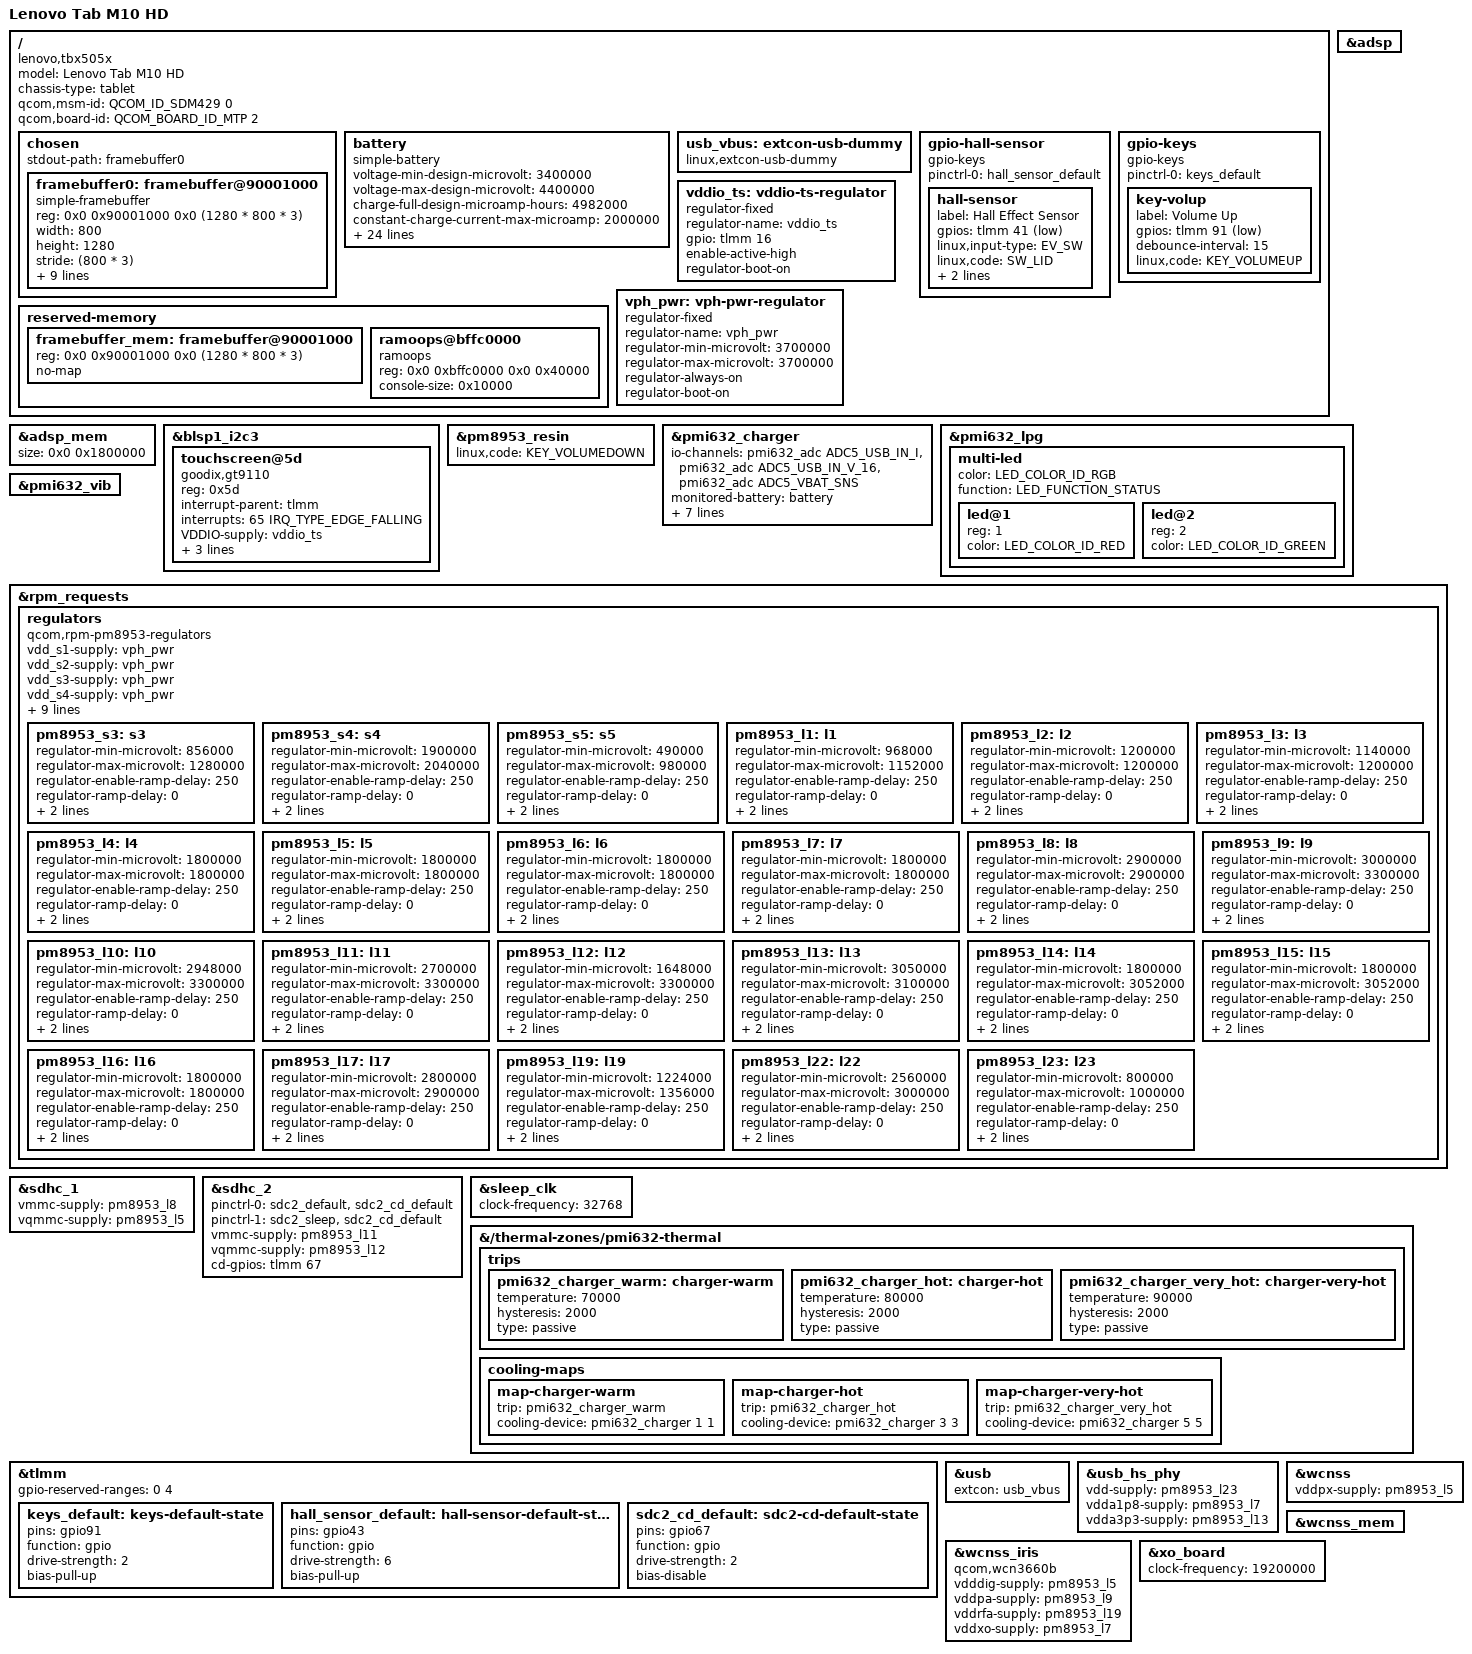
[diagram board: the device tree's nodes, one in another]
// SPDX-License-Identifier: BSD-3-Clause
/*
 * Lenovo Tab M10 HD (TB-X505X) device tree source
 *
 * Copyright (c) 2025 Kaustabh Chakraborty <kauschluss@disroot.org>
 */

/dts-v1/;
#include <dt-bindings/arm/qcom,ids.h>
#include <dt-bindings/gpio/gpio.h>
#include <dt-bindings/leds/common.h>
#include "sdm429.dtsi"
#include "pm8953.dtsi"
#include "pmi632.dtsi"

/ {
	model = "Lenovo Tab M10 HD";
	compatible = "lenovo,tbx505x", "qcom,sdm429";
	chassis-type = "tablet";

	qcom,msm-id = <QCOM_ID_SDM429 0>;
	qcom,board-id = <QCOM_BOARD_ID_MTP 2>;

	chosen {
		#address-cells = <2>;
		#size-cells = <2>;
		ranges;

		stdout-path = "framebuffer0";

		framebuffer0: framebuffer@90001000 {
			compatible = "simple-framebuffer";
			reg = <0x0 0x90001000 0x0 (1280 * 800 * 3)>;
			width = <800>;
			height = <1280>;
			stride = <(800 * 3)>;
			format = "r8g8b8";

			clocks = <&gcc GCC_MDSS_AHB_CLK>,
				 <&gcc GCC_MDSS_AXI_CLK>,
				 <&gcc GCC_MDSS_VSYNC_CLK>,
				 <&gcc GCC_MDSS_MDP_CLK>,
				 <&gcc GCC_MDSS_BYTE0_CLK>,
				 <&gcc GCC_MDSS_PCLK0_CLK>,
				 <&gcc GCC_MDSS_ESC0_CLK>;
			power-domains = <&gcc MDSS_GDSC>;
		};
	};

	battery: battery {
		compatible = "simple-battery";
		voltage-min-design-microvolt = <3400000>;
		voltage-max-design-microvolt = <4400000>;
		charge-full-design-microamp-hours = <4982000>;
		constant-charge-current-max-microamp = <2000000>;
		constant-charge-voltage-max-microvolt = <4400000>;
		charge-term-current-microamp = <170000>;
		factory-internal-resistance-micro-ohms = <120000>;
		id-resistor-ohms = <21000>;

		ocv-capacity-celsius = <25>;
		ocv-capacity-table-0 = <4382700 100>, <4361700 98>, <4339700 96>, <4314400 94>,
			<4289200 92>, <4264600 90>, <4240400 88>, <4216900 86>,
			<4194100 84>, <4171800 82>, <4149400 80>, <4128600 78>,
			<4111200 76>, <4094700 74>, <4072300 72>, <4040700 70>,
			<4014800 68>, <3999700 66>, <3987400 64>, <3973500 62>,
			<3959100 60>, <3941400 58>, <3914200 56>, <3887900 54>,
			<3872900 52>, <3862200 50>, <3852900 48>, <3844900 46>,
			<3837600 44>, <3830500 42>, <3824000 40>, <3818100 38>,
			<3812700 36>, <3807800 34>, <3803900 32>, <3800400 30>,
			<3796700 28>, <3793000 26>, <3788100 24>, <3780000 22>,
			<3769700 20>, <3758500 18>, <3745600 16>, <3730200 14>,
			<3715700 12>, <3706400 10>, <3704000 9>, <3702300 8>,
			<3700700 7>, <3697000 6>, <3675800 5>, <3634000 4>,
			<3577700 3>, <3501200 2>, <3383700 1>, <3000000 0>;
	};

	usb_vbus: extcon-usb-dummy {
		compatible = "linux,extcon-usb-dummy";
	};

	gpio-hall-sensor {
		compatible = "gpio-keys";

		pinctrl-0 = <&hall_sensor_default>;
		pinctrl-names = "default";

		hall-sensor {
			label = "Hall Effect Sensor";
			gpios = <&tlmm 41 GPIO_ACTIVE_LOW>;
			linux,input-type = <EV_SW>;
			linux,code = <SW_LID>;
			linux,can-disable;
			wakeup-source;
		};
	};

	gpio-keys {
		compatible = "gpio-keys";

		pinctrl-0 = <&keys_default>;
		pinctrl-names = "default";

		key-volup {
			label = "Volume Up";
			gpios = <&tlmm 91 GPIO_ACTIVE_LOW>;
			debounce-interval = <15>;
			linux,code = <KEY_VOLUMEUP>;
		};
	};

	reserved-memory {
		framebuffer_mem: framebuffer@90001000 {
			reg = <0x0 0x90001000 0x0 (1280 * 800 * 3)>;
			no-map;
		};

		ramoops@bffc0000 {
			compatible = "ramoops";
			reg = <0x0 0xbffc0000 0x0 0x40000>;
			console-size = <0x10000>;
		};
	};

	vddio_ts: vddio-ts-regulator {
		compatible = "regulator-fixed";
		regulator-name = "vddio_ts";
		gpio = <&tlmm 16 GPIO_ACTIVE_HIGH>;
		enable-active-high;
		regulator-boot-on;
	};

	vph_pwr: vph-pwr-regulator {
		compatible = "regulator-fixed";
		regulator-name = "vph_pwr";
		regulator-min-microvolt = <3700000>;
		regulator-max-microvolt = <3700000>;
		regulator-always-on;
		regulator-boot-on;
	};
};

&adsp {
	status = "okay";
};

&adsp_mem {
	size = <0x0 0x1800000>;

	status = "okay";
};

&blsp1_i2c3 {
	status = "okay";

	touchscreen@5d {
		compatible = "goodix,gt9110";
		reg = <0x5d>;
		interrupt-parent = <&tlmm>;
		interrupts = <65 IRQ_TYPE_EDGE_FALLING>;

		VDDIO-supply = <&vddio_ts>;
		reset-gpios = <&tlmm 64 GPIO_ACTIVE_LOW>;

		touchscreen-size-x = <800>;
		touchscreen-size-y = <1280>;
	};
};

&pm8953_resin {
	linux,code = <KEY_VOLUMEDOWN>;

	status = "okay";
};

&pmi632_charger {
	#cooling-cells = <2>;
	io-channels = <&pmi632_adc ADC5_USB_IN_I>,
		      <&pmi632_adc ADC5_USB_IN_V_16>,
		      <&pmi632_adc ADC5_VBAT_SNS>;
	io-channel-names = "usbin_i", "usbin_v", "vbat";
	monitored-battery = <&battery>;
	qcom,batt-id-pullup-ohms = <100000>;
	qcom,auto-recharge-microvolt = <4350000>;
	qcom,jeita-hard-thresholds = <0x36b9 0x0dbf>;
	qcom,jeita-soft-thresholds = <0x2554 0x0fdc>;
	qcom,jeita-soft-fcc-microamp = <975000 1000000>;
	qcom,thermal-mitigation = <2000000 1500000 1000000 800000 500000 200000>;

	status = "okay";
};

&pmi632_lpg {
	status = "okay";

	multi-led {
		color = <LED_COLOR_ID_RGB>;
		function = LED_FUNCTION_STATUS;

		#address-cells = <1>;
		#size-cells = <0>;

		led@1 {
			reg = <1>;
			color = <LED_COLOR_ID_RED>;
		};

		led@2 {
			reg = <2>;
			color = <LED_COLOR_ID_GREEN>;
		};
	};
};

&pmi632_vib {
	status = "okay";
};

&rpm_requests {
	regulators {
		compatible = "qcom,rpm-pm8953-regulators";

		vdd_s1-supply = <&vph_pwr>;
		vdd_s2-supply = <&vph_pwr>;
		vdd_s3-supply = <&vph_pwr>;
		vdd_s4-supply = <&vph_pwr>;
		vdd_s5-supply = <&vph_pwr>;
		vdd_s6-supply = <&vph_pwr>;
		vdd_s7-supply = <&vph_pwr>;
		vdd_l1-supply = <&pm8953_s3>;
		vdd_l2_l3-supply = <&pm8953_s3>;
		vdd_l4_l5_l6_l7_l16_l19-supply = <&pm8953_s4>;
		vdd_l8_l11_l12_l13_l14_l15-supply = <&vph_pwr>;
		vdd_l9_l10_l17_l18_l22-supply = <&vph_pwr>;
		vdd_l23-supply = <&pm8953_s3>;

		pm8953_s3: s3 {
			regulator-min-microvolt = <856000>;
			regulator-max-microvolt = <1280000>;
			regulator-enable-ramp-delay = <250>;
			regulator-ramp-delay = <0>;
			regulator-system-load = <100000>;
			regulator-allow-set-load;
		};

		pm8953_s4: s4 {
			regulator-min-microvolt = <1900000>;
			regulator-max-microvolt = <2040000>;
			regulator-enable-ramp-delay = <250>;
			regulator-ramp-delay = <0>;
			regulator-system-load = <100000>;
			regulator-allow-set-load;
		};

		pm8953_s5: s5 {
			regulator-min-microvolt = <490000>;
			regulator-max-microvolt = <980000>;
			regulator-enable-ramp-delay = <250>;
			regulator-ramp-delay = <0>;
			regulator-always-on;
			regulator-boot-on;
		};

		pm8953_l1: l1 {
			regulator-min-microvolt = <968000>;
			regulator-max-microvolt = <1152000>;
			regulator-enable-ramp-delay = <250>;
			regulator-ramp-delay = <0>;
			regulator-system-load = <10000>;
			regulator-allow-set-load;
		};

		pm8953_l2: l2 {
			regulator-min-microvolt = <1200000>;
			regulator-max-microvolt = <1200000>;
			regulator-enable-ramp-delay = <250>;
			regulator-ramp-delay = <0>;
			regulator-system-load = <10000>;
			regulator-allow-set-load;
		};

		pm8953_l3: l3 {
			regulator-min-microvolt = <1140000>;
			regulator-max-microvolt = <1200000>;
			regulator-enable-ramp-delay = <250>;
			regulator-ramp-delay = <0>;
			regulator-system-load = <10000>;
			regulator-allow-set-load;
		};

		pm8953_l4: l4 {
			regulator-min-microvolt = <1800000>;
			regulator-max-microvolt = <1800000>;
			regulator-enable-ramp-delay = <250>;
			regulator-ramp-delay = <0>;
			regulator-system-load = <10000>;
			regulator-allow-set-load;
		};

		pm8953_l5: l5 {
			regulator-min-microvolt = <1800000>;
			regulator-max-microvolt = <1800000>;
			regulator-enable-ramp-delay = <250>;
			regulator-ramp-delay = <0>;
			regulator-system-load = <10000>;
			regulator-allow-set-load;
		};

		pm8953_l6: l6 {
			regulator-min-microvolt = <1800000>;
			regulator-max-microvolt = <1800000>;
			regulator-enable-ramp-delay = <250>;
			regulator-ramp-delay = <0>;
			regulator-system-load = <10000>;
			regulator-allow-set-load;
		};

		pm8953_l7: l7 {
			regulator-min-microvolt = <1800000>;
			regulator-max-microvolt = <1800000>;
			regulator-enable-ramp-delay = <250>;
			regulator-ramp-delay = <0>;
			regulator-system-load = <10000>;
			regulator-allow-set-load;
		};

		pm8953_l8: l8 {
			regulator-min-microvolt = <2900000>;
			regulator-max-microvolt = <2900000>;
			regulator-enable-ramp-delay = <250>;
			regulator-ramp-delay = <0>;
			regulator-system-load = <10000>;
			regulator-allow-set-load;
		};

		pm8953_l9: l9 {
			regulator-min-microvolt = <3000000>;
			regulator-max-microvolt = <3300000>;
			regulator-enable-ramp-delay = <250>;
			regulator-ramp-delay = <0>;
			regulator-system-load = <10000>;
			regulator-allow-set-load;
		};

		pm8953_l10: l10 {
			regulator-min-microvolt = <2948000>;
			regulator-max-microvolt = <3300000>;
			regulator-enable-ramp-delay = <250>;
			regulator-ramp-delay = <0>;
			regulator-system-load = <10000>;
			regulator-allow-set-load;
		};

		pm8953_l11: l11 {
			regulator-min-microvolt = <2700000>;
			regulator-max-microvolt = <3300000>;
			regulator-enable-ramp-delay = <250>;
			regulator-ramp-delay = <0>;
			regulator-system-load = <10000>;
			regulator-allow-set-load;
		};

		pm8953_l12: l12 {
			regulator-min-microvolt = <1648000>;
			regulator-max-microvolt = <3300000>;
			regulator-enable-ramp-delay = <250>;
			regulator-ramp-delay = <0>;
			regulator-system-load = <10000>;
			regulator-allow-set-load;
		};

		pm8953_l13: l13 {
			regulator-min-microvolt = <3050000>;
			regulator-max-microvolt = <3100000>;
			regulator-enable-ramp-delay = <250>;
			regulator-ramp-delay = <0>;
			regulator-system-load = <5000>;
			regulator-allow-set-load;
		};

		pm8953_l14: l14 {
			regulator-min-microvolt = <1800000>;
			regulator-max-microvolt = <3052000>;
			regulator-enable-ramp-delay = <250>;
			regulator-ramp-delay = <0>;
			regulator-system-load = <5000>;
			regulator-allow-set-load;
		};

		pm8953_l15: l15 {
			regulator-min-microvolt = <1800000>;
			regulator-max-microvolt = <3052000>;
			regulator-enable-ramp-delay = <250>;
			regulator-ramp-delay = <0>;
			regulator-system-load = <5000>;
			regulator-allow-set-load;
		};

		pm8953_l16: l16 {
			regulator-min-microvolt = <1800000>;
			regulator-max-microvolt = <1800000>;
			regulator-enable-ramp-delay = <250>;
			regulator-ramp-delay = <0>;
			regulator-system-load = <5000>;
			regulator-allow-set-load;
		};

		pm8953_l17: l17 {
			regulator-min-microvolt = <2800000>;
			regulator-max-microvolt = <2900000>;
			regulator-enable-ramp-delay = <250>;
			regulator-ramp-delay = <0>;
			regulator-system-load = <10000>;
			regulator-allow-set-load;
		};

		pm8953_l19: l19 {
			regulator-min-microvolt = <1224000>;
			regulator-max-microvolt = <1356000>;
			regulator-enable-ramp-delay = <250>;
			regulator-ramp-delay = <0>;
			regulator-system-load = <10000>;
			regulator-allow-set-load;
		};

		pm8953_l22: l22 {
			regulator-min-microvolt = <2560000>;
			regulator-max-microvolt = <3000000>;
			regulator-enable-ramp-delay = <250>;
			regulator-ramp-delay = <0>;
			regulator-system-load = <10000>;
			regulator-allow-set-load;
		};

		pm8953_l23: l23 {
			regulator-min-microvolt = <800000>;
			regulator-max-microvolt = <1000000>;
			regulator-enable-ramp-delay = <250>;
			regulator-ramp-delay = <0>;
			regulator-system-load = <10000>;
			regulator-allow-set-load;
		};
	};
};

&sdhc_1 {
	vmmc-supply = <&pm8953_l8>;
	vqmmc-supply = <&pm8953_l5>;

	status = "okay";
};

&sdhc_2 {
	pinctrl-0 = <&sdc2_default &sdc2_cd_default>;
	pinctrl-1 = <&sdc2_sleep &sdc2_cd_default>;
	pinctrl-names = "default", "sleep";

	vmmc-supply = <&pm8953_l11>;
	vqmmc-supply = <&pm8953_l12>;
	cd-gpios = <&tlmm 67 GPIO_ACTIVE_HIGH>;

	status = "okay";
};

&sleep_clk {
	clock-frequency = <32768>;
};

&{/thermal-zones/pmi632-thermal} {
	trips {
		pmi632_charger_warm: charger-warm {
			temperature = <70000>;
			hysteresis = <2000>;
			type = "passive";
		};

		pmi632_charger_hot: charger-hot {
			temperature = <80000>;
			hysteresis = <2000>;
			type = "passive";
		};

		pmi632_charger_very_hot: charger-very-hot {
			temperature = <90000>;
			hysteresis = <2000>;
			type = "passive";
		};
	};

	cooling-maps {
		map-charger-warm {
			trip = <&pmi632_charger_warm>;
			cooling-device = <&pmi632_charger 1 1>;
		};

		map-charger-hot {
			trip = <&pmi632_charger_hot>;
			cooling-device = <&pmi632_charger 3 3>;
		};

		map-charger-very-hot {
			trip = <&pmi632_charger_very_hot>;
			cooling-device = <&pmi632_charger 5 5>;
		};
	};
};

&tlmm {
	gpio-reserved-ranges = <0 4>;

	keys_default: keys-default-state {
		pins = "gpio91";
		function = "gpio";
		drive-strength = <2>;
		bias-pull-up;
	};

	hall_sensor_default: hall-sensor-default-state {
		pins = "gpio43";
		function = "gpio";
		drive-strength = <6>;
		bias-pull-up;
	};

	sdc2_cd_default: sdc2-cd-default-state {
		pins = "gpio67";
		function = "gpio";
		drive-strength = <2>;
		bias-disable;
	};
};

&usb {
	extcon = <&usb_vbus>;

	status = "okay";
};

&usb_hs_phy {
	vdd-supply = <&pm8953_l23>;
	vdda1p8-supply = <&pm8953_l7>;
	vdda3p3-supply = <&pm8953_l13>;

	status = "okay";
};

&wcnss {
	vddpx-supply = <&pm8953_l5>;

	status = "okay";
};

&wcnss_iris {
	compatible = "qcom,wcn3660b";

	vdddig-supply = <&pm8953_l5>;
	vddpa-supply = <&pm8953_l9>;
	vddrfa-supply = <&pm8953_l19>;
	vddxo-supply = <&pm8953_l7>;
};

&wcnss_mem {
	status = "okay";
};

&xo_board {
	clock-frequency = <19200000>;
};
